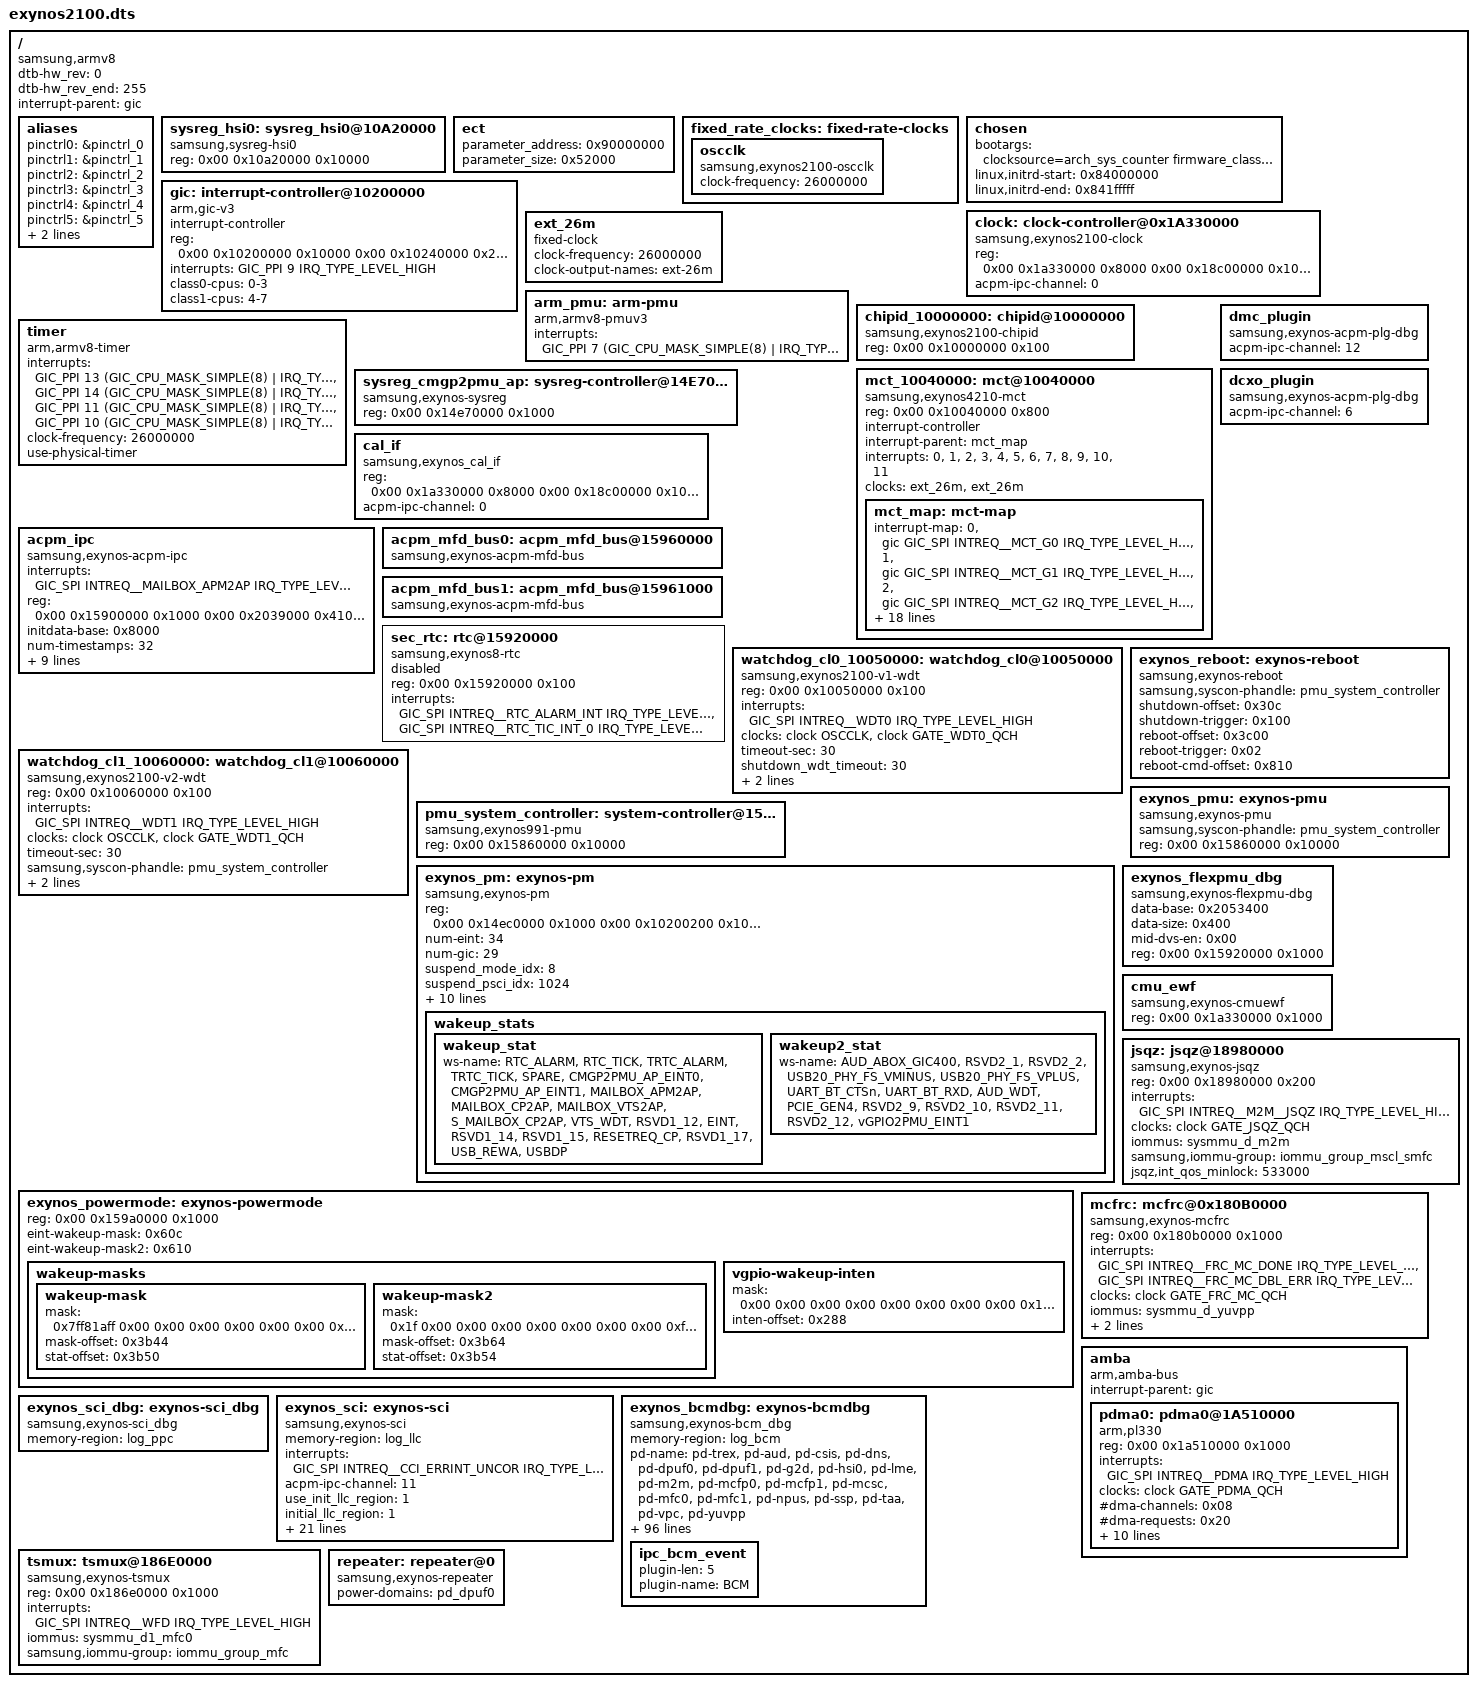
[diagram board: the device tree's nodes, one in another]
// SPDX-License-Identifier: GPL-2.0-only
/*
 * Exynos2100 SoC
 *
 * Copyright (C) 2026 Samsung Electronics Co., Ltd.
 *		http://www.samsung.com
 *
 */

/dts-v1/;
#include <dt-bindings/pci/pci.h>
#include <dt-bindings/clock/exynos2100.h>
#include <dt-bindings/interrupt-controller/exynos2100.h>
#include <dt-bindings/soc/samsung/exynos-bcm_dbg.h>
#include <dt-bindings/soc/samsung/exynos2100-devfreq.h>
#include <dt-bindings/soc/samsung/exynos2100-dm.h>
#include <dt-bindings/soc/samsung/exynos_pm_qos.h>
#include "exynos2100-rmem.dtsi"
#include "exynos2100-sysmmu.dtsi"
#include "exynos2100-ion.dtsi"
#include "exynos2100-usi.dtsi"
#include "exynos2100-pm-domains.dtsi"
#include "exynos2100-pinctrl.dtsi"
#include "exynos2100-gpu.dtsi"
#include "exynos2100-dpu.dtsi"
#include "exynos2100-security.dtsi"
#include "exynos2100-usb.dtsi"
#include "exynos2100-ufs.dtsi"
#include "exynos2100-audio.dtsi"
#include "exynos2100-debug.dtsi"
#include "exynos2100-cpu.dtsi"
#include "exynos2100-ems.dtsi"
#include "exynos2100-npu.dtsi"
#include "exynos2100-mfc.dtsi"
#include "exynos2100-pcie.dtsi"
#include "exynos2100-m2m.dtsi"
#include "exynos2100-bts.dtsi"
#include "exynos2100-power.dtsi"
#include "exynos2100-camera.dtsi"
#include "exynos2100-profiler.dtsi"
#include "exynos2100-xperf.dtsi"
#include "exynos2100-mmc.dtsi"
#include "exynos2100-pwm.dtsi"

/ {
	compatible = "samsung,armv8", "samsung,exynos2100";
	dtb-hw_rev = <0>;
	dtb-hw_rev_end = <255>;
	interrupt-parent = <&gic>;
	#address-cells = <2>;
	#size-cells = <1>;

	aliases {
		pinctrl0 = &pinctrl_0;
		pinctrl1 = &pinctrl_1;
		pinctrl2 = &pinctrl_2;
		pinctrl3 = &pinctrl_3;
		pinctrl4 = &pinctrl_4;
		pinctrl5 = &pinctrl_5;
		pinctrl6 = &pinctrl_6;
		pinctrl7 = &pinctrl_7;
	};

	sysreg_hsi0: sysreg_hsi0@10A20000 {
		compatible = "samsung,sysreg-hsi0", "syscon";
		reg = <0x00 0x10a20000 0x10000>;
	};

	ect: ect {
		parameter_address = <0x90000000>;
		parameter_size = <0x52000>;
	};

	fixed_rate_clocks: fixed-rate-clocks {
		oscclk {
			compatible = "samsung,exynos2100-oscclk";
			clock-frequency = <26000000>;
		};
	};

	chosen: chosen {
		bootargs = "clocksource=arch_sys_counter firmware_class.path=/vendor/firmware nr_cpus=8 androidboot.hardware=exynos2100 log_buf_len=256K irqaffinity=0 loop.max_part=7 rcupdate.rcu_expedited=1 s3c2410_wdt.tmr_atboot=1 s3c2410_wdt.tmr_margin=80 printk.devkmsg=on cgroup.memory=nokmem swiotlb=noforce";
		linux,initrd-start = <0x84000000>;
		linux,initrd-end = <0x841fffff>;
	};

	gic: interrupt-controller@10200000 {
		compatible = "arm,gic-v3";
		#interrupt-cells = <3>;
		interrupt-controller;
		reg = <0x00 0x10200000 0x10000 0x00 0x10240000 0x200000>;
		interrupts = <GIC_PPI 9 IRQ_TYPE_LEVEL_HIGH>;
		class0-cpus = "0-3";
		class1-cpus = "4-7";
	};

	clock: clock-controller@0x1A330000 {
		compatible = "samsung,exynos2100-clock";
		reg = <
			0x00 0x1a330000 0x8000
			0x00 0x18c00000 0x1000
			0x00 0x1a030000 0x1000
			0x00 0x1d040000 0x1000
			0x00 0x1d050000 0x1000
			0x00 0x1d060000 0x1000
			0x00 0x1d030000 0x1000
			0x00 0x10020000 0x1000>;
		#clock-cells = <1>;
		acpm-ipc-channel = <0>;
	};

	ext_26m: ext_26m {
		compatible = "fixed-clock";
		#clock-cells = <0>;
		clock-frequency = <26000000>;
		clock-output-names = "ext-26m";
	};

	arm_pmu: arm-pmu {
		compatible = "arm,armv8-pmuv3";
		interrupts = <GIC_PPI 7 (GIC_CPU_MASK_SIMPLE(8) | IRQ_TYPE_LEVEL_HIGH)>;
	};

	chipid_10000000: chipid@10000000 {
		compatible = "samsung,exynos2100-chipid";
		reg = <0x00 0x10000000 0x100>;
	};

	timer: timer {
		compatible = "arm,armv8-timer";
		interrupts =
			<GIC_PPI 13 (GIC_CPU_MASK_SIMPLE(8) | IRQ_TYPE_LEVEL_LOW)>,
			<GIC_PPI 14 (GIC_CPU_MASK_SIMPLE(8) | IRQ_TYPE_LEVEL_LOW)>,
			<GIC_PPI 11 (GIC_CPU_MASK_SIMPLE(8) | IRQ_TYPE_LEVEL_LOW)>,
			<GIC_PPI 10 (GIC_CPU_MASK_SIMPLE(8) | IRQ_TYPE_LEVEL_LOW)>;
		clock-frequency = <26000000>;
		use-physical-timer;
	};

	mct_10040000: mct@10040000 {
		compatible = "samsung,exynos4210-mct";
		reg = <0x00 0x10040000 0x800>;
		interrupt-controller;
		#interrupt-cells = <1>;
		interrupt-parent = <&mct_map>;
		interrupts = <0>, <1>, <2>, <3>,
			<4>, <5>, <6>, <7>,
			<8>, <9>, <10>, <11>;
		clocks = <&ext_26m>, <&ext_26m>;
		clock-names = "fin_pll", "mct";

		mct_map: mct-map {
			#interrupt-cells = <1>;
			#address-cells = <0>;
			#size-cells = <0>;
			interrupt-map =
				<0 &gic GIC_SPI INTREQ__MCT_G0 IRQ_TYPE_LEVEL_HIGH>,
				<1 &gic GIC_SPI INTREQ__MCT_G1 IRQ_TYPE_LEVEL_HIGH>,
				<2 &gic GIC_SPI INTREQ__MCT_G2 IRQ_TYPE_LEVEL_HIGH>,
				<3 &gic GIC_SPI INTREQ__MCT_G3 IRQ_TYPE_LEVEL_HIGH>,
				<4 &gic GIC_SPI INTREQ__MCT_L0 IRQ_TYPE_LEVEL_HIGH>,
				<5 &gic GIC_SPI INTREQ__MCT_L1 IRQ_TYPE_LEVEL_HIGH>,
				<6 &gic GIC_SPI INTREQ__MCT_L2 IRQ_TYPE_LEVEL_HIGH>,
				<7 &gic GIC_SPI INTREQ__MCT_L3 IRQ_TYPE_LEVEL_HIGH>,
				<8 &gic GIC_SPI INTREQ__MCT_L4 IRQ_TYPE_LEVEL_HIGH>,
				<9 &gic GIC_SPI INTREQ__MCT_L5 IRQ_TYPE_LEVEL_HIGH>,
				<10 &gic GIC_SPI INTREQ__MCT_L6 IRQ_TYPE_LEVEL_HIGH>,
				<11 &gic GIC_SPI INTREQ__MCT_L7 IRQ_TYPE_LEVEL_HIGH>;
		};
	};

	sysreg_cmgp2pmu_ap: sysreg-controller@14E70000 {
		compatible = "samsung,exynos-sysreg", "syscon";
		reg = <0x00 0x14e70000 0x1000>;
	};

	/* CAL-IF */
	cal_if: cal_if {
		compatible = "samsung,exynos_cal_if";
		reg = <
			0x00 0x1a330000 0x8000
			0x00 0x18c00000 0x1000
			0x00 0x1a030000 0x1000
			0x00 0x1d040000 0x1000
			0x00 0x1d050000 0x1000
			0x00 0x1d060000 0x1000
			0x00 0x1d030000 0x1000
			0x00 0x10020000 0x1000>;
		acpm-ipc-channel = <0>;
	};

	acpm_ipc: acpm_ipc {
		compatible = "samsung,exynos-acpm-ipc";
		#address-cells = <2>;
		#size-cells = <1>;
		interrupts = <GIC_SPI INTREQ__MAILBOX_APM2AP IRQ_TYPE_LEVEL_HIGH>;
		reg = <0x00 0x15900000 0x1000 0x00 0x2039000 0x41000>;
		initdata-base = <0x8000>;
		num-timestamps = <32>;
		debug-log-level = <0>;
		logging-period = <500>;
		dump-base = <0x203d000>;
		dump-size = <0x3d000>;
		dram-dump-base = <0x90014000>;
		board-id = <0x10>;
		board-rev = <0x00>;
		nfc-log-offset = <0x26400>;
		nfc-log-len = <16>;
	};

	acpm_mfd_bus0: acpm_mfd_bus@15960000 {
		compatible = "samsung,exynos-acpm-mfd-bus";
		status = "okay";
	};

	acpm_mfd_bus1: acpm_mfd_bus@15961000 {
		compatible = "samsung,exynos-acpm-mfd-bus";
		status = "okay";
	};

	dmc_plugin: dmc_plugin {
		compatible = "samsung,exynos-acpm-plg-dbg";
		acpm-ipc-channel = <12>;
	};

	dcxo_plugin: dcxo_plugin {
		compatible = "samsung,exynos-acpm-plg-dbg";
		acpm-ipc-channel = <6>;
	};

	sec_rtc: rtc@15920000 {
		compatible = "samsung,exynos8-rtc";
		reg = <0x00 0x15920000 0x100>;
		interrupts =
			<GIC_SPI INTREQ__RTC_ALARM_INT IRQ_TYPE_LEVEL_HIGH>,
			<GIC_SPI INTREQ__RTC_TIC_INT_0 IRQ_TYPE_LEVEL_HIGH>;
		status = "disabled";
	};

	watchdog_cl0_10050000: watchdog_cl0@10050000 {
		compatible = "samsung,exynos2100-v1-wdt";
		reg = <0x00 0x10050000 0x100>;
		interrupts = <GIC_SPI INTREQ__WDT0 IRQ_TYPE_LEVEL_HIGH>;
		clocks = <&clock OSCCLK>, <&clock GATE_WDT0_QCH>;
		clock-names = "rate_watchdog", "gate_watchdog";
		timeout-sec = <30>;
		shutdown_wdt_timeout = <30>;
		samsung,syscon-phandle = <&pmu_system_controller>;
		index = <0>;
		status = "okay";
	};

	watchdog_cl1_10060000: watchdog_cl1@10060000 {
		compatible = "samsung,exynos2100-v2-wdt";
		reg = <0x00 0x10060000 0x100>;
		interrupts = <GIC_SPI INTREQ__WDT1 IRQ_TYPE_LEVEL_HIGH>;
		clocks = <&clock OSCCLK>, <&clock GATE_WDT1_QCH>;
		clock-names = "rate_watchdog", "gate_watchdog";
		timeout-sec = <30>;
		samsung,syscon-phandle = <&pmu_system_controller>;
		index = <1>;
		use_multistage_wdt;
		status = "okay";
	};

	exynos_reboot: exynos-reboot {
		compatible = "samsung,exynos-reboot";
		samsung,syscon-phandle = <&pmu_system_controller>;
		shutdown-offset = <0x30c>;
		shutdown-trigger = <0x100>;
		reboot-offset = <0x3c00>;
		reboot-trigger = <0x02>;
		reboot-cmd-offset = <0x810>;
	};

	/* PMU */
	exynos_pmu: exynos-pmu {
		compatible = "samsung,exynos-pmu";
		samsung,syscon-phandle = <&pmu_system_controller>;
		reg = <0x00 0x15860000 0x10000>;
		reg-names = "pmu_alive";
	};

	pmu_system_controller: system-controller@15860000 {
		compatible = "samsung,exynos991-pmu", "syscon";
		reg = <0x00 0x15860000 0x10000>;
	};

	exynos_pm: exynos-pm {
		compatible = "samsung,exynos-pm";
		reg = <
			0x00 0x14ec0000 0x1000
			0x00 0x10200200 0x100
			0x00 0x159a0000 0x1000>;
		reg-names = "gpio_alive_base", "gicd_ispendrn_base", "sysreg_vgpio2pmu";
		num-eint = <34>;
		num-gic = <29>;
		suspend_mode_idx = <8>;
		suspend_psci_idx = <1024>;
		wakeup_stat_offset = <0x3b50 0x3b54>;
		wakeup_int_en_offset = <0x3b44 0x3b64>;
		wakeup_int_en = <0x52f6f 0x9b>;
		usbl2_wakeup_int_en = <0x00 0x18>;
		eint_wakeup_mask_offset = <0x60c 0x610>;
		wakeup-stat-eint = <13>;
		wakeup-stat-rtc = <0>;
		vgpio_wakeup_inten = <0x19>;
		vgpio_wakeup_inten_offset = <0x288>;
		wake_lock = <0>;

		wakeup_stats {
			wakeup_stat {
				ws-name =
					"RTC_ALARM",
					"RTC_TICK",
					"TRTC_ALARM",
					"TRTC_TICK",
					"SPARE",
					"CMGP2PMU_AP_EINT0",
					"CMGP2PMU_AP_EINT1",
					"MAILBOX_APM2AP",
					"MAILBOX_CP2AP",
					"MAILBOX_VTS2AP",
					"S_MAILBOX_CP2AP",
					"VTS_WDT",
					"RSVD1_12",
					"EINT",
					"RSVD1_14",
					"RSVD1_15",
					"RESETREQ_CP",
					"RSVD1_17",
					"USB_REWA",
					"USBDP";
			};

			wakeup2_stat {
				ws-name = 
					"AUD_ABOX_GIC400",
					"RSVD2_1",
					"RSVD2_2",
					"USB20_PHY_FS_VMINUS",
					"USB20_PHY_FS_VPLUS",
					"UART_BT_CTSn",
					"UART_BT_RXD",
					"AUD_WDT",
					"PCIE_GEN4",
					"RSVD2_9",
					"RSVD2_10",
					"RSVD2_11",
					"RSVD2_12",
					"vGPIO2PMU_EINT1";
			};
		};
	};

	exynos_powermode: exynos-powermode {
		reg = <0x00 0x159a0000 0x1000>;
		reg-names = "sysreg_vgpio2pmu";
		eint-wakeup-mask = <0x60c>;
		eint-wakeup-mask2 = <0x610>;

		wakeup-masks {
			wakeup-mask {
				mask = <
					0x7ff81aff 0x00 0x00 0x00 0x00
					0x00 0x00 0x00 0x52f6f 0x52f6f
					0x52f6f 0x00 0x00 0x52f6f>;
				mask-offset = <0x3b44>;
				stat-offset = <0x3b50>;
			};

			wakeup-mask2 {
				mask = <
					0x1f 0x00 0x00 0x00 0x00
					0x00 0x00 0x00 0xfb 0xfb
					0xfb 0x00 0x00 0xfb>;
				mask-offset = <0x3b64>;
				stat-offset = <0x3b54>;
			};
		};

		vgpio-wakeup-inten {
			mask = <
				0x00 0x00 0x00 0x00 0x00
				0x00 0x00 0x00 0x19 0x19
				0x19 0x00 0x19 0x19>;
			inten-offset = <0x288>;
		};
	};

	exynos_flexpmu_dbg: exynos_flexpmu_dbg {
		compatible = "samsung,exynos-flexpmu-dbg";
		#address-cells = <2>;
		#size-cells = <1>;
		data-base = <0x2053400>;
		data-size = <0x400>;
		mid-dvs-en = <0x00>;
		reg = <0x00 0x15920000 0x1000>;
	};

	cmu_ewf: cmu_ewf {
		compatible = "samsung,exynos-cmuewf";
		#address-cells = <2>;
		#size-cells = <1>;
		reg = <0x00 0x1a330000 0x1000>;
	};

	jsqz: jsqz@18980000 {
		compatible = "samsung,exynos-jsqz";
		reg = <0x00 0x18980000 0x200>;
		interrupts = <GIC_SPI INTREQ__M2M__JSQZ IRQ_TYPE_LEVEL_HIGH>;
		clocks = <&clock GATE_JSQZ_QCH>;
		clock-names = "gate";
		iommus = <&sysmmu_d_m2m>;
		samsung,iommu-group = <&iommu_group_mscl_smfc>;
		jsqz,int_qos_minlock = <533000>;
	};

	mcfrc: mcfrc@0x180B0000 {
		compatible = "samsung,exynos-mcfrc";
		reg = <0x00 0x180b0000 0x1000>;
		interrupts =
			<GIC_SPI INTREQ__FRC_MC_DONE IRQ_TYPE_LEVEL_HIGH>,
			<GIC_SPI INTREQ__FRC_MC_DBL_ERR IRQ_TYPE_LEVEL_HIGH>;
		clocks = <&clock GATE_FRC_MC_QCH>;
		clock-names = "gate";
		iommus = <&sysmmu_d_yuvpp>;
		samsung,iommu-group = <&iommu_group_is>;
		mcfrc,int_qos_minlock = <663000>;
	};

	/* DMA */
	amba: amba {
		#address-cells = <2>;
		#size-cells = <1>;
		compatible = "arm,amba-bus";
		interrupt-parent = <&gic>;
		ranges;

		pdma0: pdma0@1A510000 {
			compatible = "arm,pl330", "arm,primecell";
			reg = <0x00 0x1a510000 0x1000>;
			interrupts = <GIC_SPI INTREQ__PDMA IRQ_TYPE_LEVEL_HIGH>;
			clocks = <&clock GATE_PDMA_QCH>;
			clock-names = "apb_pclk";
			#dma-cells = <1>;
			#dma-channels = <0x08>;
			#dma-requests = <0x20>;
			#dma-multi-irq = <0x01>;
			dma-arwrapper = <0x10114400>,
				<0x10114420>,
				<0x10114440>,
				<0x10114460>,
				<0x10114480>,
				<0x101144A0>,
				<0x101144C0>,
				<0x101144E0>;
			dma-awwrapper = <0x1a514404>,
				<0x1a514424>,
				<0x1a514444>,
				<0x1a514464>,
				<0x1a514484>,
				<0x1a5144A4>,
				<0x1a5144C4>,
				<0x1a5144E4>;
			dma-instwrapper = <0x1a514500>;
			dma-mask-bit = <0x24>;
			coherent-mask-bit = <0x24>;
		};
	};

	exynos_sci_dbg: exynos-sci_dbg {
		compatible = "samsung,exynos-sci_dbg";
		memory-region = <&log_ppc>;
	};

	exynos_sci: exynos-sci {
		compatible = "samsung,exynos-sci";
		memory-region = <&log_llc>;
		interrupts = <GIC_SPI INTREQ__CCI_ERRINT_UNCOR IRQ_TYPE_LEVEL_HIGH>;
		acpm-ipc-channel = <11>;
		use_init_llc_region = <1>;
		initial_llc_region = <1>;
		ret_enable = <0>;
		llc_enable = <1>;
		hfreq_rate = <30>;
		freq_th = <2028000>;
		on_time_th = <200000000>;
		off_time_th = "SrN";
		llc_gov_en = <1>;
		region_name =
			"LLC_REGION_DISABLE",
			"LLC_REGION_CPU",
			"LLC_REGION_CALL",
			"LLC_REGION_OFFLOAD",
			"LLC_REGION_CPD2",
			"LLC_REGION_CPCPU",
			"LLC_REGION_DPU",
			"LLC_REGION_MFC0_INT",
			"LLC_REGION_MFC1_INT",
			"LLC_REGION_MFC0_DPB",
			"LLC_REGION_MFC1_DPB",
			"LLC_REGION_GPU",
			"LLC_REGION_NPU0",
			"LLC_REGION_NPU1",
			"LLC_REGION_NPU2",
			"LLC_REGION_DSP0",
			"LLC_REGION_DSP1",
			"LLC_REGION_CAM_MCFP",
			"LLC_REGION_CAM_CSIS";
		region_priority = <0 1 2 3 4 11 5 8 9 6 7 10 12 13 14 15 16 17 18>;
		cpu_min_region = <0>;
		devfreq = <&devfreq_0>;
	};

	exynos_bcmdbg: exynos-bcmdbg {
		compatible = "samsung,exynos-bcm_dbg";
		memory-region = <&log_bcm>;
		pd-name = "pd-trex", "pd-aud",
			"pd-csis", "pd-dns",
			"pd-dpuf0", "pd-dpuf1",
			"pd-g2d", "pd-hsi0",
			"pd-lme", "pd-m2m",
			"pd-mcfp0", "pd-mcfp1",
			"pd-mcsc", "pd-mfc0",
			"pd-mfc1", "pd-npus",
			"pd-ssp", "pd-taa",
			"pd-vpc", "pd-yuvpp";
		max_define_event = <PRE_DEFINE_EVT_MAX>;
		define_events =
			<NO_PRE_DEFINE_EVT	0x00  0x00  0x00  0x00  0x00  0x00  0x00  0x00>,
			<LATENCY_FMT_EVT	0x04  0x02  0x26  0x24  0x05  0x03  0x27  0x25>,
			<MO_FMT_EVT	0x04  0x00  0x24  0x24  0x05  0x01  0x25  0x25>,
			<BURST_LENGTH_FMT_EVT	0x04  0x02  0x04  0x26  0x05  0x03  0x05  0x27>,
			<REQ_BLOCK_FMT_EVT	0x02  0x10  0x10  0x26  0x03  0x11  0x11  0x27>,
			<DATA_BLOCK_FMT_EVT	0x04  0x12  0x12  0x06  0x05  0x13  0x13  0x14>,
			<REQ_TYPE_FMT_EVT	0x02  0x15  0x18  0x1b  0x03  0x16  0x19  0x1c>,
			<BCM_CALC_FMT_EVT	0x04  0x05  0x20  0x23  0x00  0x01  0x24  0x25>;
		default_define_event = <LATENCY_FMT_EVT>;
		define_filter_id =
			<NO_PRE_DEFINE_EVT	0x00  0x00>,
			<LATENCY_FMT_EVT	0x00  0x00>,
			<MO_FMT_EVT	0x00  0x00>,
			<BURST_LENGTH_FMT_EVT	0x00  0x00>,
			<REQ_BLOCK_FMT_EVT	0x00  0x00>,
			<DATA_BLOCK_FMT_EVT	0x00  0x00>,
			<REQ_TYPE_FMT_EVT	0x00  0x00>,
			<BCM_CALC_FMT_EVT	0x00  0x00>;
		define_filter_id_active =
			<NO_PRE_DEFINE_EVT	0x00  0x00  0x00  0x00  0x00  0x00  0x00  0x00>,
			<LATENCY_FMT_EVT	0x00  0x00  0x00  0x00  0x00  0x00  0x00  0x00>,
			<MO_FMT_EVT	0x00  0x00  0x00  0x00  0x00  0x00  0x00  0x00>,
			<BURST_LENGTH_FMT_EVT	0x00  0x00  0x00  0x00  0x00  0x00  0x00  0x00>,
			<REQ_BLOCK_FMT_EVT	0x00  0x00  0x00  0x00  0x00  0x00  0x00  0x00>,
			<DATA_BLOCK_FMT_EVT	0x00  0x00  0x00  0x00  0x00  0x00  0x00  0x00>,
			<REQ_TYPE_FMT_EVT	0x00  0x00  0x00  0x00  0x00  0x00  0x00  0x00>,
			<BCM_CALC_FMT_EVT	0x00  0x00  0x00  0x00  0x00  0x00  0x00  0x00>;
		define_filter_other_0 =
			<NO_PRE_DEFINE_EVT	0x00  0x00  0x00>,
			<LATENCY_FMT_EVT	0x00  0x00  0x00>,
			<MO_FMT_EVT	0x00  0x00  0x00>,
			<BURST_LENGTH_FMT_EVT	0x00  0x00  0x00>,
			<REQ_BLOCK_FMT_EVT	0x00  0x00  0x00>,
			<DATA_BLOCK_FMT_EVT	0x00  0x00  0x00>,
			<REQ_TYPE_FMT_EVT	0x00  0x00  0x00>,
			<BCM_CALC_FMT_EVT	0x00  0x00  0x00>;
		define_filter_other_1 =
			<NO_PRE_DEFINE_EVT	0x00  0x00  0x00>,
			<LATENCY_FMT_EVT	0x00  0x00  0x00>,
			<MO_FMT_EVT	0x00  0x00  0x00>,
			<BURST_LENGTH_FMT_EVT	0x00  0x00  0x00>,
			<REQ_BLOCK_FMT_EVT	0x00  0x00  0x00>,
			<DATA_BLOCK_FMT_EVT	0x00  0x00  0x00>,
			<REQ_TYPE_FMT_EVT	0x00  0x00  0x00>,
			<BCM_CALC_FMT_EVT	0x00  0x00  0x00>;
		define_filter_other_active =
			<NO_PRE_DEFINE_EVT	0x00  0x00  0x00  0x00  0x00  0x00  0x00  0x00>,
			<LATENCY_FMT_EVT	0x00  0x00  0x00  0x00  0x00  0x00  0x00  0x00>,
			<MO_FMT_EVT	0x00  0x00  0x00  0x00  0x00  0x00  0x00  0x00>,
			<BURST_LENGTH_FMT_EVT	0x00  0x00  0x00  0x00  0x00  0x00  0x00  0x00>,
			<REQ_BLOCK_FMT_EVT	0x00  0x00  0x00  0x00  0x00  0x00  0x00  0x00>,
			<DATA_BLOCK_FMT_EVT	0x00  0x00  0x00  0x00  0x00  0x00  0x00  0x00>,
			<REQ_TYPE_FMT_EVT	0x00  0x00  0x00  0x00  0x00  0x00  0x00  0x00>,
			<BCM_CALC_FMT_EVT	0x00  0x00  0x00  0x00  0x00  0x00  0x00  0x00>;
		define_sample_id =
			<NO_PRE_DEFINE_EVT	0x00  0x00>,
			<LATENCY_FMT_EVT	0x00  0x00>,
			<MO_FMT_EVT	0x00  0x00>,
			<BURST_LENGTH_FMT_EVT	0x00  0x00>,
			<REQ_BLOCK_FMT_EVT	0x00  0x00>,
			<DATA_BLOCK_FMT_EVT	0x00  0x00>,
			<REQ_TYPE_FMT_EVT	0x00  0x00>,
			<BCM_CALC_FMT_EVT	0x00  0x00>;
		define_sample_id_enable =
			<NO_PRE_DEFINE_EVT	0x00  0x00  0x00  0x00  0x00  0x00  0x00  0x00>,
			<LATENCY_FMT_EVT	0x00  0x00  0x01  0x00  0x00  0x00  0x01  0x00>,
			<MO_FMT_EVT	0x00  0x00  0x01  0x00  0x00  0x00  0x01  0x00>,
			<BURST_LENGTH_FMT_EVT	0x00  0x00  0x01  0x01  0x00  0x00  0x01  0x01>,
			<REQ_BLOCK_FMT_EVT	0x00  0x00  0x01  0x01  0x00  0x00  0x01  0x01>,
			<DATA_BLOCK_FMT_EVT	0x00  0x00  0x01  0x00  0x00  0x00  0x01  0x00>,
			<REQ_TYPE_FMT_EVT	0x00  0x00  0x00  0x00  0x00  0x00  0x00  0x00>,
			<BCM_CALC_FMT_EVT	0x00  0x00  0x00  0x00  0x00  0x00  0x00  0x00>;
		bcm_cnt_nr = <8>;
		bcm_ip_nr = <71>;
		bcm_ip_print_nr = <10>;
		initial_run_bcm_ip = <0>, <1>, <2>, <3>, <4>, <5>, <6>, <7>, <8>, <9>, <10>,
			<11>, <12>, <13>, <14>, <15>, <16>, <17>, <18>, <19>, <20>, <21>,
			<22>, <23>, <24>, <25>, <26>, <27>, <28>, <29>, <30>, <31>, <32>,
			<33>, <34>, <35>, <36>, <38>, <39>, <40>, <41>, <42>, <43>, <44>,
			<45>, <46>, <47>, <48>, <49>, <50>, <51>, <52>, <53>, <54>, <55>,
			<56>, <57>, <58>, <59>, <60>, <61>, <62>, <63>, <64>, <65>, <66>,
			<67>, <68>, <69>, <70>;
		initial_bcm_run = <BCM_STOP>;
		initial_period = <1>;
		initial_bcm_mode = <BCM_MODE_INTERVAL>;
		available_stop_owner = <PANIC_HANDLE CAMERA_DRIVER MODEM_IF ITMON_HANDLE>;
		buff_size = <0x200000>;
		glb_auto_en = <1>;
		bcm_calc_num_ip = <4>;
		bcm_calc_ip_idx = <1>, <3>, <62>, <67>;
		bcm_calc_ip_name = "CPUCL0_0", "G3D0", "IRPS0", "MIF0";
		bcm_calc_ip_cnt = <2>, <4>, <4>, <4>;
		bcm_calc_bus_width = <32>, <16>, <32>, <16>;
		bcm_calc_sample_time = <50>;
		perf_define_event = <BCM_CALC_FMT_EVT>;

		ipc_bcm_event {
			plugin-len = <5>;
			plugin-name = "BCM";
		};
	};

	tsmux: tsmux@186E0000 {
		compatible = "samsung,exynos-tsmux";
		reg = <0x00 0x186e0000 0x1000>;
		interrupts = <GIC_SPI INTREQ__WFD IRQ_TYPE_LEVEL_HIGH>;
		iommus = <&sysmmu_d1_mfc0>;
		samsung,iommu-group = <&iommu_group_mfc>;
	};

	repeater: repeater@0 {
		compatible = "samsung,exynos-repeater";
		power-domains = <&pd_dpuf0>;
	};
};
